VERSION ""

NS_ :

BS_:

BU_:

BO_ 3221225472 VECTOR__INDEPENDENT_SIG_MSG: 0 Vector__XXX
 SG_ NewSignal_0008 : 56|8@1+ (1,0) [0|0] "" Vector__XXX
 SG_ NewSignal_0009 : 56|8@1+ (1,0) [0|0] "" Vector__XXX
 SG_ NewSignal_0007 : 48|8@1+ (1,0) [0|0] "" Vector__XXX
 SG_ NewSignal_0006 : 40|8@1+ (1,0) [0|0] "" Vector__XXX
 SG_ NewSignal_0005 : 32|8@1+ (1,0) [0|0] "" Vector__XXX
 SG_ NewSignal_0004 : 24|8@1+ (1,0) [0|0] "" Vector__XXX
 SG_ NewSignal_0003 : 16|8@1+ (1,0) [0|0] "" Vector__XXX
 SG_ Diff_Pressure_Switch_State : 32|2@1+ (1,0) [0|0] "" Vector__XXX

BO_ 1 Heartbeat: 8 Vector__XXX
 SG_ Version : 0|8@1+ (1,0) [0|0] "" Vector__XXX
 SG_ Heartbeat_Counter : 56|8@1+ (1,0) [0|255] "" Vector__XXX

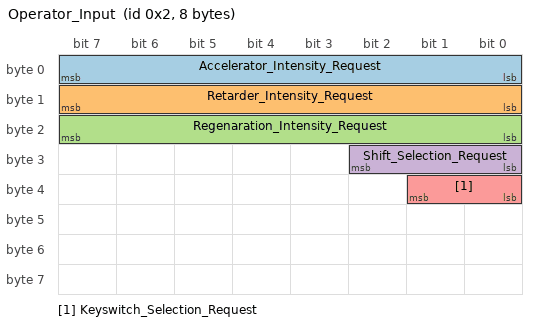
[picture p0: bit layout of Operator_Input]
BO_ 2 Operator_Input: 8 Vector__XXX
 SG_ Accelerator_Intensity_Request : 0|8@1+ (1,0) [0|100] "" Vector__XXX
 SG_ Retarder_Intensity_Request : 8|8@1+ (1,0) [0|100] "" Vector__XXX
 SG_ Regenaration_Intensity_Request : 16|8@1+ (1,0) [0|100] "" Vector__XXX
 SG_ Shift_Selection_Request : 24|3@1+ (1,0) [0|4] "" Vector__XXX
 SG_ Keyswitch_Selection_Request : 32|2@1+ (1,0) [0|3] "" Vector__XXX

BO_ 3 Diagnostics: 8 Vector__XXX
 SG_ Error_Code : 0|8@1+ (1,0) [0|0] "" Vector__XXX

BO_ 4 Internal_States: 8 Vector__XXX

VAL_ 2 Shift_Selection_Request 0 "INVALID" 1 "PARK" 2 "REVERSE" 3 "NEUTRAL" 4 "DRIVE" ;
VAL_ 2 Keyswitch_Selection_Request 0 "INVALID" 1 "IDLE" 2 "IGNTION" 3 "ENGINE_START" ;
